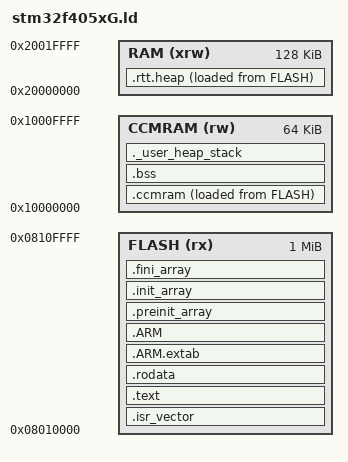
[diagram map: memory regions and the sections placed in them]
/*
*****************************************************************************
**
**  Abstract    : Linker script for STM32F405xG Device with
**                1024KByte FLASH, 128KByte RAM
**
**                Set heap size, stack size and stack location according
**                to application requirements.
**
**                Set memory bank area and size if external memory is used.
**
**                Use ccram for .data, .bss, heap, and stack.
**
**  Target      : STMicroelectronics STM32
**
**  Environment : GNU Tools for ARM Embedded Processors
**
**
**  (c)Copyright armink.
**
*****************************************************************************
*/

/* Entry Point */
ENTRY(Reset_Handler)

/* Highest address of the user mode stack */
_estack = 0x2001FFFF;    /* end of RAM */

/* Generate a link error if heap and stack don't fit into RAM */
_Min_Heap_Size = 0x200;      /* required amount of heap  */
_Min_Stack_Size = 0x400; /* required amount of stack */

/* Specify the memory areas */
MEMORY
{
FLASH (rx)      : ORIGIN = 0x8000000 + 64*1024, LENGTH = 1024K
RAM (xrw)      : ORIGIN = 0x20000000, LENGTH = 128K
CCMRAM (rw)      : ORIGIN = 0x10000000, LENGTH = 64K
}

/* Define output sections */
SECTIONS
{
  /* The startup code goes first into FLASH */
  .isr_vector :
  {
    . = ALIGN(4);
    KEEP(*(.isr_vector)) /* Startup code */
    . = ALIGN(4);
  } >FLASH

  /* The program code and other data goes into FLASH */
  .text :
  {
    _stext = .;        /* define a global symbols at start of code */
    . = ALIGN(4);
    *(.text)           /* .text sections (code) */
    *(.text*)          /* .text* sections (code) */
    *(.glue_7)         /* glue arm to thumb code */
    *(.glue_7t)        /* glue thumb to arm code */
    *(.eh_frame)

    KEEP (*(.init))
    KEEP (*(.fini))
    
    . = ALIGN(4);
    _etext = .;        /* define a global symbols at end of code */
  } >FLASH

  /* Constant data goes into FLASH */
  .rodata :
  {
    . = ALIGN(4);
    *(.rodata)         /* .rodata sections (constants, strings, etc.) */
    *(.rodata*)        /* .rodata* sections (constants, strings, etc.) */
    . = ALIGN(4);
    
    /* section information for RT-thread finsh shell */
    . = ALIGN(4);
    __fsymtab_start = .;
    KEEP(*(FSymTab))
    __fsymtab_end = .;
    . = ALIGN(4);
    __vsymtab_start = .;
    KEEP(*(VSymTab))
    __vsymtab_end = .;
    . = ALIGN(4);

    /* section information for RT-Thread components initial. */
    . = ALIGN(4);
    __rt_init_start = .;
    KEEP(*(SORT(.rti_fn*)))
    __rt_init_end = .;
    . = ALIGN(4);
    
  } >FLASH

  .ARM.extab   : { *(.ARM.extab* .gnu.linkonce.armextab.*) } >FLASH
  .ARM : {
    __exidx_start = .;
    *(.ARM.exidx*)
    __exidx_end = .;
  } >FLASH

  .preinit_array     :
  {
    PROVIDE_HIDDEN (__preinit_array_start = .);
    KEEP (*(.preinit_array*))
    PROVIDE_HIDDEN (__preinit_array_end = .);
  } >FLASH
  .init_array :
  {
    PROVIDE_HIDDEN (__init_array_start = .);
    KEEP (*(SORT(.init_array.*)))
    KEEP (*(.init_array*))
    PROVIDE_HIDDEN (__init_array_end = .);
  } >FLASH
  .fini_array :
  {
    PROVIDE_HIDDEN (__fini_array_start = .);
    KEEP (*(SORT(.fini_array.*)))
    KEEP (*(.fini_array*))
    PROVIDE_HIDDEN (__fini_array_end = .);
  } >FLASH

  /* Initialized RT-Thread heap sections goes into RAM, load LMA copy after code */
  .rtt.heap : 
  {
    . = ALIGN(4);

    . = ALIGN(4);

  } >RAM AT> FLASH
  
  /* used by the startup to initialize data */
  _sidata = LOADADDR(.ccmram);
  _siccmram = LOADADDR(.ccmram);

  /* CCM-RAM section 
  * 
  * IMPORTANT NOTE! 
  * If initialized variables will be placed in this section, 
  * the startup code needs to be modified to copy the init-values.  
  */
  .ccmram :
  {
    . = ALIGN(4);
    _sdata = .;         /* create a global symbol at data start */
    _sccmram = .;       /* create a global symbol at ccmram start */
    *(.data)            /* .data sections */
    *(.data*)           /* .data* sections */
    *(.ccmram)
    *(.ccmram*)
    
    . = ALIGN(4);
    _eccmram = .;       /* create a global symbol at ccmram end */
    _edata = .;         /* define a global symbol at data end */
  } >CCMRAM AT> FLASH

  
  /* Uninitialized data section */
  . = ALIGN(4);
  .bss :
  {
    /* This is used by the startup in order to initialize the .bss secion */
    _sbss = .;         /* define a global symbol at bss start */
    __bss_start__ = _sbss;
    *(.bss)
    *(.bss*)
    *(COMMON)

    . = ALIGN(4);
    _ebss = .;         /* define a global symbol at bss end */
    __bss_end__ = _ebss;
  } >CCMRAM

  /* User_heap_stack section, used to check that there is enough CCRAM left */
  ._user_heap_stack :
  {
    . = ALIGN(4);
    PROVIDE ( end = . );
    PROVIDE ( _end = . );
    . = . + _Min_Heap_Size;
    _sstack = .;       /* create a global symbol at stack start */
    . = . + _Min_Stack_Size;
    _estack = .;       /* create a global symbol at stack end */
    . = ALIGN(4);
  } >CCMRAM

  

  /* Remove information from the standard libraries */
  /DISCARD/ :
  {
    libc.a ( * )
    libm.a ( * )
    libgcc.a ( * )
  }

  .ARM.attributes 0 : { *(.ARM.attributes) }
}
